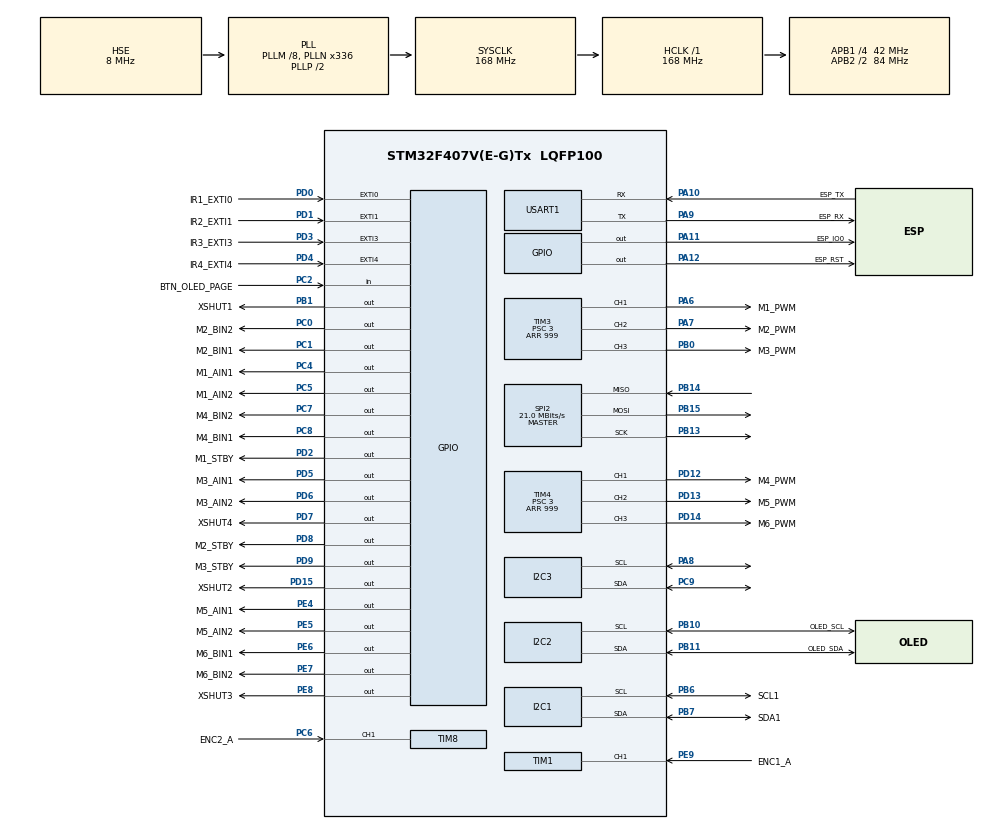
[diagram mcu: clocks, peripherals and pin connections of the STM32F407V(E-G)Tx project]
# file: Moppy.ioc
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Dma.I2C1_RX.3.Direction=DMA_PERIPH_TO_MEMORY
Dma.I2C1_RX.3.FIFOMode=DMA_FIFOMODE_DISABLE
Dma.I2C1_RX.3.Instance=DMA1_Stream0
Dma.I2C1_RX.3.MemDataAlignment=DMA_MDATAALIGN_BYTE
Dma.I2C1_RX.3.MemInc=DMA_MINC_ENABLE
Dma.I2C1_RX.3.Mode=DMA_NORMAL
Dma.I2C1_RX.3.PeriphDataAlignment=DMA_PDATAALIGN_BYTE
Dma.I2C1_RX.3.PeriphInc=DMA_PINC_DISABLE
Dma.I2C1_RX.3.Priority=DMA_PRIORITY_VERY_HIGH
Dma.I2C1_TX.4.Direction=DMA_MEMORY_TO_PERIPH
Dma.I2C1_TX.4.FIFOMode=DMA_FIFOMODE_DISABLE
Dma.I2C1_TX.4.Instance=DMA1_Stream6
Dma.I2C1_TX.4.MemDataAlignment=DMA_MDATAALIGN_BYTE
Dma.I2C1_TX.4.MemInc=DMA_MINC_ENABLE
Dma.I2C1_TX.4.Mode=DMA_NORMAL
Dma.I2C1_TX.4.PeriphDataAlignment=DMA_PDATAALIGN_BYTE
Dma.I2C1_TX.4.PeriphInc=DMA_PINC_DISABLE
Dma.I2C1_TX.4.Priority=DMA_PRIORITY_HIGH
Dma.I2C2_TX.2.Direction=DMA_MEMORY_TO_PERIPH
Dma.I2C2_TX.2.FIFOMode=DMA_FIFOMODE_DISABLE
Dma.I2C2_TX.2.Instance=DMA1_Stream7
Dma.I2C2_TX.2.MemDataAlignment=DMA_MDATAALIGN_BYTE
Dma.I2C2_TX.2.MemInc=DMA_MINC_ENABLE
Dma.I2C2_TX.2.Mode=DMA_NORMAL
Dma.I2C2_TX.2.PeriphDataAlignment=DMA_PDATAALIGN_BYTE
Dma.I2C2_TX.2.PeriphInc=DMA_PINC_DISABLE
Dma.I2C2_TX.2.Priority=DMA_PRIORITY_LOW
Dma.I2C3_RX.5.Direction=DMA_PERIPH_TO_MEMORY
Dma.I2C3_RX.5.FIFOMode=DMA_FIFOMODE_DISABLE
Dma.I2C3_RX.5.Instance=DMA1_Stream2
Dma.I2C3_RX.5.MemDataAlignment=DMA_MDATAALIGN_BYTE
Dma.I2C3_RX.5.MemInc=DMA_MINC_ENABLE
Dma.I2C3_RX.5.Mode=DMA_NORMAL
Dma.I2C3_RX.5.PeriphDataAlignment=DMA_PDATAALIGN_BYTE
Dma.I2C3_RX.5.PeriphInc=DMA_PINC_DISABLE
Dma.I2C3_RX.5.Priority=DMA_PRIORITY_VERY_HIGH
Dma.I2C3_TX.6.Direction=DMA_MEMORY_TO_PERIPH
Dma.I2C3_TX.6.FIFOMode=DMA_FIFOMODE_DISABLE
Dma.I2C3_TX.6.Instance=DMA1_Stream4
Dma.I2C3_TX.6.MemDataAlignment=DMA_MDATAALIGN_BYTE
Dma.I2C3_TX.6.MemInc=DMA_MINC_ENABLE
Dma.I2C3_TX.6.Mode=DMA_NORMAL
Dma.I2C3_TX.6.PeriphDataAlignment=DMA_PDATAALIGN_BYTE
Dma.I2C3_TX.6.PeriphInc=DMA_PINC_DISABLE
Dma.I2C3_TX.6.Priority=DMA_PRIORITY_HIGH
Dma.Request0=USART1_RX
Dma.Request1=USART1_TX
Dma.Request2=I2C2_TX
Dma.Request3=I2C1_RX
Dma.Request4=I2C1_TX
Dma.Request5=I2C3_RX
Dma.Request6=I2C3_TX
Dma.USART1_RX.0.Direction=DMA_PERIPH_TO_MEMORY
Dma.USART1_RX.0.FIFOMode=DMA_FIFOMODE_DISABLE
Dma.USART1_RX.0.Instance=DMA2_Stream2
Dma.USART1_RX.0.MemDataAlignment=DMA_MDATAALIGN_BYTE
Dma.USART1_RX.0.MemInc=DMA_MINC_ENABLE
Dma.USART1_RX.0.Mode=DMA_CIRCULAR
Dma.USART1_RX.0.PeriphDataAlignment=DMA_PDATAALIGN_BYTE
Dma.USART1_RX.0.PeriphInc=DMA_PINC_DISABLE
Dma.USART1_RX.0.Priority=DMA_PRIORITY_HIGH
Dma.USART1_TX.1.Direction=DMA_MEMORY_TO_PERIPH
Dma.USART1_TX.1.FIFOMode=DMA_FIFOMODE_DISABLE
Dma.USART1_TX.1.Instance=DMA2_Stream7
Dma.USART1_TX.1.MemDataAlignment=DMA_MDATAALIGN_BYTE
Dma.USART1_TX.1.MemInc=DMA_MINC_ENABLE
Dma.USART1_TX.1.Mode=DMA_NORMAL
Dma.USART1_TX.1.PeriphDataAlignment=DMA_PDATAALIGN_BYTE
Dma.USART1_TX.1.PeriphInc=DMA_PINC_DISABLE
Dma.USART1_TX.1.Priority=DMA_PRIORITY_LOW
I2C1.I2C_Mode=I2C_Fast
I2C2.I2C_Mode=I2C_Fast
I2C3.I2C_Mode=I2C_Fast
Mcu.Family=STM32F4
Mcu.Name=STM32F407V(E-G)Tx
Mcu.Package=LQFP100
NVIC.DMA1_Stream0_IRQn=true\:0\:0\:false\:false\:true\:false\:true\:true
NVIC.DMA1_Stream2_IRQn=true\:0\:0\:false\:false\:true\:false\:true\:true
NVIC.DMA1_Stream4_IRQn=true\:0\:0\:false\:false\:true\:false\:true\:true
NVIC.DMA1_Stream6_IRQn=true\:0\:0\:false\:false\:true\:false\:true\:true
NVIC.DMA1_Stream7_IRQn=true\:0\:0\:false\:false\:true\:false\:true\:true
NVIC.DMA2_Stream2_IRQn=true\:0\:0\:false\:false\:true\:false\:true\:true
NVIC.DMA2_Stream7_IRQn=true\:0\:0\:false\:false\:true\:false\:true\:true
NVIC.I2C1_ER_IRQn=true\:0\:0\:false\:false\:true\:true\:true\:true
NVIC.I2C1_EV_IRQn=true\:0\:0\:false\:false\:true\:true\:true\:true
NVIC.I2C2_EV_IRQn=true\:0\:0\:false\:false\:true\:true\:true\:true
NVIC.I2C3_ER_IRQn=true\:0\:0\:false\:false\:true\:true\:true\:true
NVIC.I2C3_EV_IRQn=true\:0\:0\:false\:false\:true\:true\:true\:true
NVIC.PriorityGroup=NVIC_PRIORITYGROUP_4
NVIC.TIM1_CC_IRQn=true\:0\:0\:false\:false\:true\:true\:true\:true
NVIC.TIM6_DAC_IRQn=true\:0\:0\:false\:false\:true\:true\:true\:true
NVIC.TIM8_CC_IRQn=true\:0\:0\:false\:false\:true\:true\:true\:true
NVIC.USART1_IRQn=true\:0\:0\:false\:false\:true\:true\:true\:true
PA10.GPIO_Label=ESP_TX
PA10.Mode=Asynchronous
PA10.Signal=USART1_RX
PA11.GPIO_Label=ESP_IO0
PA11.Signal=GPIO_Output
PA12.GPIO_Label=ESP_RST
PA12.Signal=GPIO_Output
PA13.Mode=Serial_Wire
PA13.Signal=SYS_JTMS-SWDIO
PA14.Mode=Serial_Wire
PA14.Signal=SYS_JTCK-SWCLK
PA6.GPIO_Label=M1_PWM
PA6.Signal=S_TIM3_CH1
PA7.GPIO_Label=M2_PWM
PA7.Signal=S_TIM3_CH2
PA8.Mode=I2C
PA8.Signal=I2C3_SCL
PA9.GPIO_Label=ESP_RX
PA9.Mode=Asynchronous
PA9.Signal=USART1_TX
PB0.GPIO_Label=M3_PWM
PB0.GPIO_Speed=GPIO_SPEED_FREQ_VERY_HIGH
PB0.Signal=S_TIM3_CH3
PB1.GPIO_Label=XSHUT1
PB1.GPIO_ModeDefaultOutputPP=GPIO_MODE_OUTPUT_PP
PB1.GPIO_PuPd=GPIO_NOPULL
PB1.GPIO_Speed=GPIO_SPEED_FREQ_LOW
PB1.PinState=GPIO_PIN_RESET
PB1.Signal=GPIO_Output
PB10.GPIO_Label=OLED_SCL
PB10.Mode=I2C
PB10.Signal=I2C2_SCL
PB11.GPIO_Label=OLED_SDA
PB11.Mode=I2C
PB11.Signal=I2C2_SDA
PB13.Mode=Full_Duplex_Master
PB13.Signal=SPI2_SCK
PB14.Mode=Full_Duplex_Master
PB14.Signal=SPI2_MISO
PB15.Mode=Full_Duplex_Master
PB15.Signal=SPI2_MOSI
PB6.GPIO_Label=SCL1
PB6.Mode=I2C
PB6.Signal=I2C1_SCL
PB7.GPIO_Label=SDA1
PB7.Mode=I2C
PB7.Signal=I2C1_SDA
PC0.GPIO_Label=M2_BIN2
PC0.GPIO_PuPd=GPIO_NOPULL
PC0.Signal=GPIO_Output
PC1.GPIO_Label=M2_BIN1
PC1.Signal=GPIO_Output
PC2.GPIO_Label=BTN_OLED_PAGE
PC2.GPIO_PuPd=GPIO_PULLUP
PC2.Signal=GPIO_Input
PC4.GPIO_Label=M1_AIN1
PC4.Signal=GPIO_Output
PC5.GPIO_Label=M1_AIN2
PC5.Signal=GPIO_Output
PC6.GPIO_Label=ENC2_A
PC6.Signal=S_TIM8_CH1
PC7.GPIO_Label=M4_BIN2
PC7.Signal=GPIO_Output
PC8.GPIO_Label=M4_BIN1
PC8.Signal=GPIO_Output
PC9.Mode=I2C
PC9.Signal=I2C3_SDA
PD0.GPIO_Label=IR1_EXTI0
PD0.Signal=GPXTI0
PD1.GPIO_Label=IR2_EXTI1
PD1.Signal=GPXTI1
PD12.GPIO_Label=M4_PWM
PD12.GPIO_Speed=GPIO_SPEED_FREQ_VERY_HIGH
PD12.Signal=S_TIM4_CH1
PD13.GPIO_Label=M5_PWM
PD13.GPIO_Speed=GPIO_SPEED_FREQ_VERY_HIGH
PD13.Signal=S_TIM4_CH2
PD14.GPIO_Label=M6_PWM
PD14.GPIO_Speed=GPIO_SPEED_FREQ_VERY_HIGH
PD14.Signal=S_TIM4_CH3
PD15.GPIO_Label=XSHUT2
PD15.Signal=GPIO_Output
PD2.GPIO_Label=M1_STBY
PD2.Signal=GPIO_Output
PD3.GPIO_Label=IR3_EXTI3
PD3.Signal=GPXTI3
PD4.GPIO_Label=IR4_EXTI4
PD4.Signal=GPXTI4
PD5.GPIO_Label=M3_AIN1
PD5.Signal=GPIO_Output
PD6.GPIO_Label=M3_AIN2
PD6.Signal=GPIO_Output
PD7.GPIO_Label=XSHUT4
PD7.GPIO_ModeDefaultOutputPP=GPIO_MODE_OUTPUT_PP
PD7.GPIO_PuPd=GPIO_NOPULL
PD7.GPIO_Speed=GPIO_SPEED_FREQ_LOW
PD7.PinState=GPIO_PIN_RESET
PD7.Signal=GPIO_Output
PD8.GPIO_Label=M2_STBY
PD8.Signal=GPIO_Output
PD9.GPIO_Label=M3_STBY
PD9.Signal=GPIO_Output
PE4.GPIO_Label=M5_AIN1
PE4.Signal=GPIO_Output
PE5.GPIO_Label=M5_AIN2
PE5.Signal=GPIO_Output
PE6.GPIO_Label=M6_BIN1
PE6.Signal=GPIO_Output
PE7.GPIO_Label=M6_BIN2
PE7.Signal=GPIO_Output
PE8.GPIO_Label=XSHUT3
PE8.Signal=GPIO_Output
PE9.GPIO_Label=ENC1_A
PE9.GPIO_PuPd=GPIO_PULLUP
PE9.Signal=S_TIM1_CH1
PH0-OSC_IN.Mode=HSE-External-Oscillator
PH0-OSC_IN.Signal=RCC_OSC_IN
PH1-OSC_OUT.Mode=HSE-External-Oscillator
PH1-OSC_OUT.Signal=RCC_OSC_OUT
ProjectManager.HeapSize=0x200
ProjectManager.StackSize=0x400
ProjectManager.TargetToolchain=STM32CubeIDE
RCC.48MHZClocksFreq_Value=84000000
RCC.AHBFreq_Value=168000000
RCC.APB1CLKDivider=RCC_HCLK_DIV4
RCC.APB1Freq_Value=42000000
RCC.APB1TimFreq_Value=84000000
RCC.APB2CLKDivider=RCC_HCLK_DIV2
RCC.APB2Freq_Value=84000000
RCC.APB2TimFreq_Value=168000000
RCC.CortexFreq_Value=168000000
RCC.HCLKFreq_Value=168000000
RCC.HSE_VALUE=8000000
RCC.HSI_VALUE=16000000
RCC.LSE_VALUE=32768
RCC.PLLM=8
RCC.PLLN=336
RCC.PLLSourceVirtual=RCC_PLLSOURCE_HSE
RCC.SYSCLKFreq_VALUE=168000000
RCC.SYSCLKSource=RCC_SYSCLKSOURCE_PLLCLK
RCC.VCOOutputFreq_Value=336000000
SH.S_TIM1_CH1.0=TIM1_CH1,Input_Capture1_from_TI1
SH.S_TIM3_CH1.0=TIM3_CH1,PWM Generation1 CH1
SH.S_TIM3_CH2.0=TIM3_CH2,PWM Generation2 CH2
SH.S_TIM3_CH3.0=TIM3_CH3,PWM Generation3 CH3
SH.S_TIM4_CH1.0=TIM4_CH1,PWM Generation1 CH1
SH.S_TIM4_CH2.0=TIM4_CH2,PWM Generation2 CH2
SH.S_TIM4_CH3.0=TIM4_CH3,PWM Generation3 CH3
SH.S_TIM8_CH1.0=TIM8_CH1,Input_Capture1_from_TI1
SPI2.CalculateBaudRate=21.0 MBits/s
SPI2.Direction=SPI_DIRECTION_2LINES
SPI2.Mode=SPI_MODE_MASTER
SPI2.VirtualType=VM_MASTER
TIM1.Channel-Input_Capture1_from_TI1=TIM_CHANNEL_1
TIM1.Prescaler=83
TIM3.AutoReloadPreload=TIM_AUTORELOAD_PRELOAD_ENABLE
TIM3.Channel-PWM\ Generation1\ CH1=TIM_CHANNEL_1
TIM3.Channel-PWM\ Generation2\ CH2=TIM_CHANNEL_2
TIM3.Channel-PWM\ Generation3\ CH3=TIM_CHANNEL_3
TIM3.Period=999
TIM3.Prescaler=3
TIM4.AutoReloadPreload=TIM_AUTORELOAD_PRELOAD_ENABLE
TIM4.Channel-PWM\ Generation1\ CH1=TIM_CHANNEL_1
TIM4.Channel-PWM\ Generation2\ CH2=TIM_CHANNEL_2
TIM4.Channel-PWM\ Generation3\ CH3=TIM_CHANNEL_3
TIM4.Period=999
TIM4.Prescaler=3
TIM6.Period=9
TIM6.Prescaler=8399
TIM6.TIM_MasterOutputTrigger=TIM_TRGO_UPDATE
TIM8.Channel-Input_Capture1_from_TI1=TIM_CHANNEL_1
TIM8.Prescaler=83
USART1.VirtualMode=VM_ASYNC
VP_TIM1_VS_ClockSourceINT.Mode=Internal
VP_TIM3_VS_ClockSourceINT.Mode=Internal
VP_TIM4_VS_ClockSourceINT.Mode=Internal
VP_TIM6_VS_ClockSourceINT.Mode=Enable_Timer
VP_TIM8_VS_ClockSourceINT.Mode=Internal
board=custom

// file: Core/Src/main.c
/* USER CODE BEGIN Header */
/**
  ******************************************************************************
  * @file           : main.c
  * @brief          : Main program body
  ******************************************************************************
  * @attention
  *
  * Copyright (c) 2026 STMicroelectronics.
  * All rights reserved.
  *
  * This software is licensed under terms that can be found in the LICENSE file
  * in the root directory of this software component.
  * If no LICENSE file comes with this software, it is provided AS-IS.
  *
  ******************************************************************************
  */
/* USER CODE END Header */
#include "main.h"

/* USER CODE BEGIN Includes */
#include "general.h"
/* USER CODE END Includes */

I2C_HandleTypeDef hi2c1;
I2C_HandleTypeDef hi2c2;
I2C_HandleTypeDef hi2c3;
DMA_HandleTypeDef hdma_i2c1_rx;
DMA_HandleTypeDef hdma_i2c1_tx;
DMA_HandleTypeDef hdma_i2c2_tx;
DMA_HandleTypeDef hdma_i2c3_rx;
DMA_HandleTypeDef hdma_i2c3_tx;

SPI_HandleTypeDef hspi2;

TIM_HandleTypeDef htim1;
TIM_HandleTypeDef htim3;
TIM_HandleTypeDef htim4;
TIM_HandleTypeDef htim6;
TIM_HandleTypeDef htim8;

UART_HandleTypeDef huart1;
DMA_HandleTypeDef hdma_usart1_rx;
DMA_HandleTypeDef hdma_usart1_tx;

void SystemClock_Config(void);
static void MX_GPIO_Init(void);
static void MX_DMA_Init(void);
static void MX_I2C1_Init(void);
static void MX_I2C2_Init(void);
static void MX_TIM3_Init(void);
static void MX_TIM4_Init(void);
static void MX_TIM6_Init(void);
static void MX_USART1_UART_Init(void);
static void MX_TIM1_Init(void);
static void MX_TIM8_Init(void);
static void MX_SPI2_Init(void);
static void MX_I2C3_Init(void);

int main(void)
{

  /* MCU Configuration--------------------------------------------------------*/

  /* Reset of all peripherals, Initializes the Flash interface and the Systick. */
  HAL_Init();

  /* Configure the system clock */
  SystemClock_Config();

  /* Initialize all configured peripherals */
  MX_GPIO_Init();
  MX_DMA_Init();
  MX_I2C1_Init();
  MX_I2C2_Init();
  MX_TIM3_Init();
  MX_TIM4_Init();
  MX_TIM6_Init();
  MX_USART1_UART_Init();
  MX_TIM1_Init();
  MX_TIM8_Init();
  MX_SPI2_Init();
  MX_I2C3_Init();
  /* USER CODE BEGIN 2 */
  GENERAL_Init();
  /* USER CODE END 2 */

  /* Infinite loop */
  /* USER CODE BEGIN WHILE */
  while (1)
  {
	  GENERAL_Update();
    /* USER CODE END WHILE */

  }
}

void SystemClock_Config(void)
{
  RCC_OscInitTypeDef RCC_OscInitStruct = {0};
  RCC_ClkInitTypeDef RCC_ClkInitStruct = {0};

  /** Configure the main internal regulator output voltage
  */
  __HAL_RCC_PWR_CLK_ENABLE();
  __HAL_PWR_VOLTAGESCALING_CONFIG(PWR_REGULATOR_VOLTAGE_SCALE1);

  /** Initializes the RCC Oscillators according to the specified parameters
  * in the RCC_OscInitTypeDef structure.
  */
  RCC_OscInitStruct.OscillatorType = RCC_OSCILLATORTYPE_HSE;
  RCC_OscInitStruct.HSEState = RCC_HSE_ON;
  RCC_OscInitStruct.PLL.PLLState = RCC_PLL_ON;
  RCC_OscInitStruct.PLL.PLLSource = RCC_PLLSOURCE_HSE;
  RCC_OscInitStruct.PLL.PLLM = 8;
  RCC_OscInitStruct.PLL.PLLN = 336;
  RCC_OscInitStruct.PLL.PLLP = RCC_PLLP_DIV2;
  RCC_OscInitStruct.PLL.PLLQ = 4;
  if (HAL_RCC_OscConfig(&RCC_OscInitStruct) != HAL_OK)
  {
    Error_Handler();
  }

  /** Initializes the CPU, AHB and APB buses clocks
  */
  RCC_ClkInitStruct.ClockType = RCC_CLOCKTYPE_HCLK|RCC_CLOCKTYPE_SYSCLK
                              |RCC_CLOCKTYPE_PCLK1|RCC_CLOCKTYPE_PCLK2;
  RCC_ClkInitStruct.SYSCLKSource = RCC_SYSCLKSOURCE_PLLCLK;
  RCC_ClkInitStruct.AHBCLKDivider = RCC_SYSCLK_DIV1;
  RCC_ClkInitStruct.APB1CLKDivider = RCC_HCLK_DIV4;
  RCC_ClkInitStruct.APB2CLKDivider = RCC_HCLK_DIV2;

  if (HAL_RCC_ClockConfig(&RCC_ClkInitStruct, FLASH_LATENCY_5) != HAL_OK)
  {
    Error_Handler();
  }
}

static void MX_I2C1_Init(void)
{

  hi2c1.Instance = I2C1;
  hi2c1.Init.ClockSpeed = 400000;
  hi2c1.Init.DutyCycle = I2C_DUTYCYCLE_2;
  hi2c1.Init.OwnAddress1 = 0;
  hi2c1.Init.AddressingMode = I2C_ADDRESSINGMODE_7BIT;
  hi2c1.Init.DualAddressMode = I2C_DUALADDRESS_DISABLE;
  hi2c1.Init.OwnAddress2 = 0;
  hi2c1.Init.GeneralCallMode = I2C_GENERALCALL_DISABLE;
  hi2c1.Init.NoStretchMode = I2C_NOSTRETCH_DISABLE;
  if (HAL_I2C_Init(&hi2c1) != HAL_OK)
  {
    Error_Handler();
  }

}

static void MX_I2C2_Init(void)
{

  hi2c2.Instance = I2C2;
  hi2c2.Init.ClockSpeed = 400000;
  hi2c2.Init.DutyCycle = I2C_DUTYCYCLE_2;
  hi2c2.Init.OwnAddress1 = 0;
  hi2c2.Init.AddressingMode = I2C_ADDRESSINGMODE_7BIT;
  hi2c2.Init.DualAddressMode = I2C_DUALADDRESS_DISABLE;
  hi2c2.Init.OwnAddress2 = 0;
  hi2c2.Init.GeneralCallMode = I2C_GENERALCALL_DISABLE;
  hi2c2.Init.NoStretchMode = I2C_NOSTRETCH_DISABLE;
  if (HAL_I2C_Init(&hi2c2) != HAL_OK)
  {
    Error_Handler();
  }

}

static void MX_I2C3_Init(void)
{

  hi2c3.Instance = I2C3;
  hi2c3.Init.ClockSpeed = 400000;
  hi2c3.Init.DutyCycle = I2C_DUTYCYCLE_2;
  hi2c3.Init.OwnAddress1 = 0;
  hi2c3.Init.AddressingMode = I2C_ADDRESSINGMODE_7BIT;
  hi2c3.Init.DualAddressMode = I2C_DUALADDRESS_DISABLE;
  hi2c3.Init.OwnAddress2 = 0;
  hi2c3.Init.GeneralCallMode = I2C_GENERALCALL_DISABLE;
  hi2c3.Init.NoStretchMode = I2C_NOSTRETCH_DISABLE;
  if (HAL_I2C_Init(&hi2c3) != HAL_OK)
  {
    Error_Handler();
  }

}

static void MX_SPI2_Init(void)
{

  /* SPI2 parameter configuration*/
  hspi2.Instance = SPI2;
  hspi2.Init.Mode = SPI_MODE_MASTER;
  hspi2.Init.Direction = SPI_DIRECTION_2LINES;
  hspi2.Init.DataSize = SPI_DATASIZE_8BIT;
  hspi2.Init.CLKPolarity = SPI_POLARITY_LOW;
  hspi2.Init.CLKPhase = SPI_PHASE_1EDGE;
  hspi2.Init.NSS = SPI_NSS_SOFT;
  hspi2.Init.BaudRatePrescaler = SPI_BAUDRATEPRESCALER_2;
  hspi2.Init.FirstBit = SPI_FIRSTBIT_MSB;
  hspi2.Init.TIMode = SPI_TIMODE_DISABLE;
  hspi2.Init.CRCCalculation = SPI_CRCCALCULATION_DISABLE;
  hspi2.Init.CRCPolynomial = 10;
  if (HAL_SPI_Init(&hspi2) != HAL_OK)
  {
    Error_Handler();
  }

}

static void MX_TIM1_Init(void)
{

  TIM_ClockConfigTypeDef sClockSourceConfig = {0};
  TIM_MasterConfigTypeDef sMasterConfig = {0};
  TIM_IC_InitTypeDef sConfigIC = {0};

  htim1.Instance = TIM1;
  htim1.Init.Prescaler = 83;
  htim1.Init.CounterMode = TIM_COUNTERMODE_UP;
  htim1.Init.Period = 65535;
  htim1.Init.ClockDivision = TIM_CLOCKDIVISION_DIV1;
  htim1.Init.RepetitionCounter = 0;
  htim1.Init.AutoReloadPreload = TIM_AUTORELOAD_PRELOAD_DISABLE;
  if (HAL_TIM_Base_Init(&htim1) != HAL_OK)
  {
    Error_Handler();
  }
  sClockSourceConfig.ClockSource = TIM_CLOCKSOURCE_INTERNAL;
  if (HAL_TIM_ConfigClockSource(&htim1, &sClockSourceConfig) != HAL_OK)
  {
    Error_Handler();
  }
  if (HAL_TIM_IC_Init(&htim1) != HAL_OK)
  {
    Error_Handler();
  }
  sMasterConfig.MasterOutputTrigger = TIM_TRGO_RESET;
  sMasterConfig.MasterSlaveMode = TIM_MASTERSLAVEMODE_DISABLE;
  if (HAL_TIMEx_MasterConfigSynchronization(&htim1, &sMasterConfig) != HAL_OK)
  {
    Error_Handler();
  }
  sConfigIC.ICPolarity = TIM_INPUTCHANNELPOLARITY_RISING;
  sConfigIC.ICSelection = TIM_ICSELECTION_DIRECTTI;
  sConfigIC.ICPrescaler = TIM_ICPSC_DIV1;
  sConfigIC.ICFilter = 0;
  if (HAL_TIM_IC_ConfigChannel(&htim1, &sConfigIC, TIM_CHANNEL_1) != HAL_OK)
  {
    Error_Handler();
  }

}

static void MX_TIM3_Init(void)
{

  TIM_ClockConfigTypeDef sClockSourceConfig = {0};
  TIM_MasterConfigTypeDef sMasterConfig = {0};
  TIM_OC_InitTypeDef sConfigOC = {0};

  htim3.Instance = TIM3;
  htim3.Init.Prescaler = 3;
  htim3.Init.CounterMode = TIM_COUNTERMODE_UP;
  htim3.Init.Period = 999;
  htim3.Init.ClockDivision = TIM_CLOCKDIVISION_DIV1;
  htim3.Init.AutoReloadPreload = TIM_AUTORELOAD_PRELOAD_ENABLE;
  if (HAL_TIM_Base_Init(&htim3) != HAL_OK)
  {
    Error_Handler();
  }
  sClockSourceConfig.ClockSource = TIM_CLOCKSOURCE_INTERNAL;
  if (HAL_TIM_ConfigClockSource(&htim3, &sClockSourceConfig) != HAL_OK)
  {
    Error_Handler();
  }
  if (HAL_TIM_PWM_Init(&htim3) != HAL_OK)
  {
    Error_Handler();
  }
  sMasterConfig.MasterOutputTrigger = TIM_TRGO_RESET;
  sMasterConfig.MasterSlaveMode = TIM_MASTERSLAVEMODE_DISABLE;
  if (HAL_TIMEx_MasterConfigSynchronization(&htim3, &sMasterConfig) != HAL_OK)
  {
    Error_Handler();
  }
  sConfigOC.OCMode = TIM_OCMODE_PWM1;
  sConfigOC.Pulse = 0;
  sConfigOC.OCPolarity = TIM_OCPOLARITY_HIGH;
  sConfigOC.OCFastMode = TIM_OCFAST_DISABLE;
  if (HAL_TIM_PWM_ConfigChannel(&htim3, &sConfigOC, TIM_CHANNEL_1) != HAL_OK)
  {
    Error_Handler();
  }
  if (HAL_TIM_PWM_ConfigChannel(&htim3, &sConfigOC, TIM_CHANNEL_2) != HAL_OK)
  {
    Error_Handler();
  }
  if (HAL_TIM_PWM_ConfigChannel(&htim3, &sConfigOC, TIM_CHANNEL_3) != HAL_OK)
  {
    Error_Handler();
  }
  HAL_TIM_MspPostInit(&htim3);

}

static void MX_TIM4_Init(void)
{

  TIM_ClockConfigTypeDef sClockSourceConfig = {0};
  TIM_MasterConfigTypeDef sMasterConfig = {0};
  TIM_OC_InitTypeDef sConfigOC = {0};

  htim4.Instance = TIM4;
  htim4.Init.Prescaler = 3;
  htim4.Init.CounterMode = TIM_COUNTERMODE_UP;
  htim4.Init.Period = 999;
  htim4.Init.ClockDivision = TIM_CLOCKDIVISION_DIV1;
  htim4.Init.AutoReloadPreload = TIM_AUTORELOAD_PRELOAD_ENABLE;
  if (HAL_TIM_Base_Init(&htim4) != HAL_OK)
  {
    Error_Handler();
  }
  sClockSourceConfig.ClockSource = TIM_CLOCKSOURCE_INTERNAL;
  if (HAL_TIM_ConfigClockSource(&htim4, &sClockSourceConfig) != HAL_OK)
  {
    Error_Handler();
  }
  if (HAL_TIM_PWM_Init(&htim4) != HAL_OK)
  {
    Error_Handler();
  }
  sMasterConfig.MasterOutputTrigger = TIM_TRGO_RESET;
  sMasterConfig.MasterSlaveMode = TIM_MASTERSLAVEMODE_DISABLE;
  if (HAL_TIMEx_MasterConfigSynchronization(&htim4, &sMasterConfig) != HAL_OK)
  {
    Error_Handler();
  }
  sConfigOC.OCMode = TIM_OCMODE_PWM1;
  sConfigOC.Pulse = 0;
  sConfigOC.OCPolarity = TIM_OCPOLARITY_HIGH;
  sConfigOC.OCFastMode = TIM_OCFAST_DISABLE;
  if (HAL_TIM_PWM_ConfigChannel(&htim4, &sConfigOC, TIM_CHANNEL_1) != HAL_OK)
  {
    Error_Handler();
  }
  if (HAL_TIM_PWM_ConfigChannel(&htim4, &sConfigOC, TIM_CHANNEL_2) != HAL_OK)
  {
    Error_Handler();
  }
  if (HAL_TIM_PWM_ConfigChannel(&htim4, &sConfigOC, TIM_CHANNEL_3) != HAL_OK)
  {
    Error_Handler();
  }
  HAL_TIM_MspPostInit(&htim4);

}

static void MX_TIM6_Init(void)
{

  TIM_MasterConfigTypeDef sMasterConfig = {0};

  htim6.Instance = TIM6;
  htim6.Init.Prescaler = 8399;
  htim6.Init.CounterMode = TIM_COUNTERMODE_UP;
  htim6.Init.Period = 9;
  htim6.Init.AutoReloadPreload = TIM_AUTORELOAD_PRELOAD_DISABLE;
  if (HAL_TIM_Base_Init(&htim6) != HAL_OK)
  {
    Error_Handler();
  }
  sMasterConfig.MasterOutputTrigger = TIM_TRGO_UPDATE;
  sMasterConfig.MasterSlaveMode = TIM_MASTERSLAVEMODE_DISABLE;
  if (HAL_TIMEx_MasterConfigSynchronization(&htim6, &sMasterConfig) != HAL_OK)
  {
    Error_Handler();
  }

}

static void MX_TIM8_Init(void)
{

  TIM_ClockConfigTypeDef sClockSourceConfig = {0};
  TIM_MasterConfigTypeDef sMasterConfig = {0};
  TIM_IC_InitTypeDef sConfigIC = {0};

  htim8.Instance = TIM8;
  htim8.Init.Prescaler = 83;
  htim8.Init.CounterMode = TIM_COUNTERMODE_UP;
  htim8.Init.Period = 65535;
  htim8.Init.ClockDivision = TIM_CLOCKDIVISION_DIV1;
  htim8.Init.RepetitionCounter = 0;
  htim8.Init.AutoReloadPreload = TIM_AUTORELOAD_PRELOAD_DISABLE;
  if (HAL_TIM_Base_Init(&htim8) != HAL_OK)
  {
    Error_Handler();
  }
  sClockSourceConfig.ClockSource = TIM_CLOCKSOURCE_INTERNAL;
  if (HAL_TIM_ConfigClockSource(&htim8, &sClockSourceConfig) != HAL_OK)
  {
    Error_Handler();
  }
  if (HAL_TIM_IC_Init(&htim8) != HAL_OK)
  {
    Error_Handler();
  }
  sMasterConfig.MasterOutputTrigger = TIM_TRGO_RESET;
  sMasterConfig.MasterSlaveMode = TIM_MASTERSLAVEMODE_DISABLE;
  if (HAL_TIMEx_MasterConfigSynchronization(&htim8, &sMasterConfig) != HAL_OK)
  {
    Error_Handler();
  }
  sConfigIC.ICPolarity = TIM_INPUTCHANNELPOLARITY_RISING;
  sConfigIC.ICSelection = TIM_ICSELECTION_DIRECTTI;
  sConfigIC.ICPrescaler = TIM_ICPSC_DIV1;
  sConfigIC.ICFilter = 0;
  if (HAL_TIM_IC_ConfigChannel(&htim8, &sConfigIC, TIM_CHANNEL_1) != HAL_OK)
  {
    Error_Handler();
  }

}

static void MX_USART1_UART_Init(void)
{

  huart1.Instance = USART1;
  huart1.Init.BaudRate = 115200;
  huart1.Init.WordLength = UART_WORDLENGTH_8B;
  huart1.Init.StopBits = UART_STOPBITS_1;
  huart1.Init.Parity = UART_PARITY_NONE;
  huart1.Init.Mode = UART_MODE_TX_RX;
  huart1.Init.HwFlowCtl = UART_HWCONTROL_NONE;
  huart1.Init.OverSampling = UART_OVERSAMPLING_16;
  if (HAL_UART_Init(&huart1) != HAL_OK)
  {
    Error_Handler();
  }

}

static void MX_DMA_Init(void)
{

  /* DMA controller clock enable */
  __HAL_RCC_DMA2_CLK_ENABLE();
  __HAL_RCC_DMA1_CLK_ENABLE();

  /* DMA interrupt init */
  /* DMA1_Stream0_IRQn interrupt configuration */
  HAL_NVIC_SetPriority(DMA1_Stream0_IRQn, 0, 0);
  HAL_NVIC_EnableIRQ(DMA1_Stream0_IRQn);
  /* DMA1_Stream2_IRQn interrupt configuration */
  HAL_NVIC_SetPriority(DMA1_Stream2_IRQn, 0, 0);
  HAL_NVIC_EnableIRQ(DMA1_Stream2_IRQn);
  /* DMA1_Stream4_IRQn interrupt configuration */
  HAL_NVIC_SetPriority(DMA1_Stream4_IRQn, 0, 0);
  HAL_NVIC_EnableIRQ(DMA1_Stream4_IRQn);
  /* DMA1_Stream6_IRQn interrupt configuration */
  HAL_NVIC_SetPriority(DMA1_Stream6_IRQn, 0, 0);
  HAL_NVIC_EnableIRQ(DMA1_Stream6_IRQn);
  /* DMA1_Stream7_IRQn interrupt configuration */
  HAL_NVIC_SetPriority(DMA1_Stream7_IRQn, 0, 0);
  HAL_NVIC_EnableIRQ(DMA1_Stream7_IRQn);
  /* DMA2_Stream2_IRQn interrupt configuration */
  HAL_NVIC_SetPriority(DMA2_Stream2_IRQn, 0, 0);
  HAL_NVIC_EnableIRQ(DMA2_Stream2_IRQn);
  /* DMA2_Stream7_IRQn interrupt configuration */
  HAL_NVIC_SetPriority(DMA2_Stream7_IRQn, 0, 0);
  HAL_NVIC_EnableIRQ(DMA2_Stream7_IRQn);

}

static void MX_GPIO_Init(void)
{
  GPIO_InitTypeDef GPIO_InitStruct = {0};

  /* GPIO Ports Clock Enable */
  __HAL_RCC_GPIOE_CLK_ENABLE();
  __HAL_RCC_GPIOH_CLK_ENABLE();
  __HAL_RCC_GPIOC_CLK_ENABLE();
  __HAL_RCC_GPIOA_CLK_ENABLE();
  __HAL_RCC_GPIOB_CLK_ENABLE();
  __HAL_RCC_GPIOD_CLK_ENABLE();

  /*Configure GPIO pin Output Level */
  HAL_GPIO_WritePin(GPIOE, M5_AIN1_Pin|M5_AIN2_Pin|M6_BIN1_Pin|M6_BIN2_Pin
                          |XSHUT3_Pin, GPIO_PIN_RESET);

  /*Configure GPIO pin Output Level */
  HAL_GPIO_WritePin(GPIOC, M2_BIN2_Pin|M2_BIN1_Pin|M1_AIN1_Pin|M1_AIN2_Pin
                          |M4_BIN2_Pin|M4_BIN1_Pin, GPIO_PIN_RESET);

  /*Configure GPIO pin Output Level */
  HAL_GPIO_WritePin(XSHUT1_GPIO_Port, XSHUT1_Pin, GPIO_PIN_RESET);

  /*Configure GPIO pin Output Level */
  HAL_GPIO_WritePin(GPIOD, M2_STBY_Pin|M3_STBY_Pin|XSHUT2_Pin|M1_STBY_Pin
                          |M3_AIN1_Pin|M3_AIN2_Pin|XSHUT4_Pin, GPIO_PIN_RESET);

  /*Configure GPIO pin Output Level */
  HAL_GPIO_WritePin(GPIOA, ESP_IO0_Pin|ESP_RST_Pin, GPIO_PIN_RESET);

  /*Configure GPIO pins : M5_AIN1_Pin M5_AIN2_Pin M6_BIN1_Pin M6_BIN2_Pin
                           XSHUT3_Pin */
  GPIO_InitStruct.Pin = M5_AIN1_Pin|M5_AIN2_Pin|M6_BIN1_Pin|M6_BIN2_Pin
                          |XSHUT3_Pin;
  GPIO_InitStruct.Mode = GPIO_MODE_OUTPUT_PP;
  GPIO_InitStruct.Pull = GPIO_NOPULL;
  GPIO_InitStruct.Speed = GPIO_SPEED_FREQ_LOW;
  HAL_GPIO_Init(GPIOE, &GPIO_InitStruct);

  /*Configure GPIO pins : M2_BIN2_Pin M2_BIN1_Pin M1_AIN1_Pin M1_AIN2_Pin
                           M4_BIN2_Pin M4_BIN1_Pin */
  GPIO_InitStruct.Pin = M2_BIN2_Pin|M2_BIN1_Pin|M1_AIN1_Pin|M1_AIN2_Pin
                          |M4_BIN2_Pin|M4_BIN1_Pin;
  GPIO_InitStruct.Mode = GPIO_MODE_OUTPUT_PP;
  GPIO_InitStruct.Pull = GPIO_NOPULL;
  GPIO_InitStruct.Speed = GPIO_SPEED_FREQ_LOW;
  HAL_GPIO_Init(GPIOC, &GPIO_InitStruct);

  /*Configure GPIO pin : BTN_OLED_PAGE_Pin */
  GPIO_InitStruct.Pin = BTN_OLED_PAGE_Pin;
  GPIO_InitStruct.Mode = GPIO_MODE_INPUT;
  GPIO_InitStruct.Pull = GPIO_PULLUP;
  HAL_GPIO_Init(BTN_OLED_PAGE_GPIO_Port, &GPIO_InitStruct);

  /*Configure GPIO pin : XSHUT1_Pin */
  GPIO_InitStruct.Pin = XSHUT1_Pin;
  GPIO_InitStruct.Mode = GPIO_MODE_OUTPUT_PP;
  GPIO_InitStruct.Pull = GPIO_NOPULL;
  GPIO_InitStruct.Speed = GPIO_SPEED_FREQ_LOW;
  HAL_GPIO_Init(XSHUT1_GPIO_Port, &GPIO_InitStruct);

  /*Configure GPIO pins : M2_STBY_Pin M3_STBY_Pin XSHUT2_Pin M1_STBY_Pin
                           M3_AIN1_Pin M3_AIN2_Pin XSHUT4_Pin */
  GPIO_InitStruct.Pin = M2_STBY_Pin|M3_STBY_Pin|XSHUT2_Pin|M1_STBY_Pin
                          |M3_AIN1_Pin|M3_AIN2_Pin|XSHUT4_Pin;
  GPIO_InitStruct.Mode = GPIO_MODE_OUTPUT_PP;
  GPIO_InitStruct.Pull = GPIO_NOPULL;
  GPIO_InitStruct.Speed = GPIO_SPEED_FREQ_LOW;
  HAL_GPIO_Init(GPIOD, &GPIO_InitStruct);

  /*Configure GPIO pins : ESP_IO0_Pin ESP_RST_Pin */
  GPIO_InitStruct.Pin = ESP_IO0_Pin|ESP_RST_Pin;
  GPIO_InitStruct.Mode = GPIO_MODE_OUTPUT_PP;
  GPIO_InitStruct.Pull = GPIO_NOPULL;
  GPIO_InitStruct.Speed = GPIO_SPEED_FREQ_LOW;
  HAL_GPIO_Init(GPIOA, &GPIO_InitStruct);

  /*Configure GPIO pins : IR1_EXTI0_Pin IR2_EXTI1_Pin IR3_EXTI3_Pin IR4_EXTI4_Pin */
  GPIO_InitStruct.Pin = IR1_EXTI0_Pin|IR2_EXTI1_Pin|IR3_EXTI3_Pin|IR4_EXTI4_Pin;
  GPIO_InitStruct.Mode = GPIO_MODE_IT_RISING;
  GPIO_InitStruct.Pull = GPIO_NOPULL;
  HAL_GPIO_Init(GPIOD, &GPIO_InitStruct);

}

void Error_Handler(void)
{
  __disable_irq();
  while (1)
  {
  }
}
